# M460 register map
File version: 1.0
Registers are 32-bit, read-write, reset 0x0 unless marked. A register's access mark holds for its fields unless they carry their own. Offsets are from the block's base; [hi:lo] are bit positions.

## CRYPTO — CRYPTO Register Map
Base 0x40032000
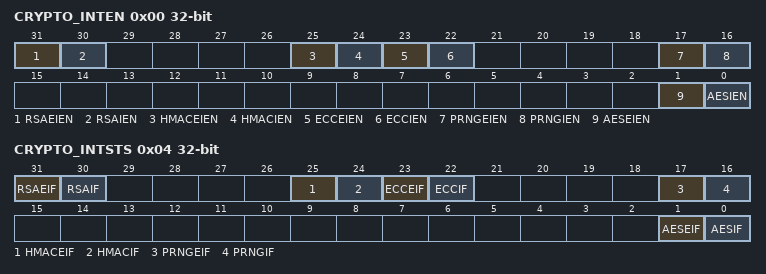
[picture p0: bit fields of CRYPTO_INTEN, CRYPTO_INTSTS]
0x00 CRYPTO_INTEN — Crypto Interrupt Enable Control Register
  [31] RSAEIEN — RSA Error Interrupt Enable Bit
    0=RSA error interrupt flag Disabled; 1=RSA error interrupt flag Enabled
  [30] RSAIEN — RSA Interrupt Enable Bit
    0=RSA interrupt Disabled; 1=RSA interrupt Enabled
  [25] HMACEIEN — SHA/HMAC Error Interrupt Enable Bit
    0=SHA/HMAC error interrupt flag Disabled; 1=HMAC error interrupt flag Enabled
  [24] HMACIEN — SHA/HMAC Interrupt Enable Bit. Note: In DMA mode, an interrupt will be triggered when an amount of data set in HMAC_DMA_CNT is fed into the SHA/HMAC engine. In Non-DMA mode, an interrupt will be triggered when the SHA/HMAC engine finishes the operation.
    0=SHA/HMAC interrupt Disabled; 1=SHA/HMAC interrupt Enabled
  [23] ECCEIEN — ECC Error Interrupt Enable Bit
    0=ECC error interrupt flag Disabled; 1=ECC error interrupt flag Enabled
  [22] ECCIEN — ECC Interrupt Enable Bit. Note: In DMA mode, an interrupt will be triggered when an amount of data set in ECC_DMA_CNT is fed into the ECC engine. In Non-DMA mode, an interrupt will be triggered when the ECC engine finishes the operation.
    0=ECC interrupt Disabled; 1=ECC interrupt Enabled
  [17] PRNGEIEN — PRNG Error Flag Enable Bit
    0=PRNG error interrupt flag Disabled; 1=PRNG error interrupt flag Enabled
  [16] PRNGIEN — PRNG Interrupt Enable Bit
    0=PRNG interrupt Disabled; 1=PRNG interrupt Enabled
  [1] AESEIEN — AES Error Flag Enable Bit
    0=AES error interrupt flag Disabled; 1=AES error interrupt flag Enabled
  [0] AESIEN — AES Interrupt Enable Bit. Note: In DMA mode, an interrupt will be triggered when an amount of data set in AES_DMA_CNT is fed into the AES engine. In Non-DMA mode, an interrupt will be triggered when the AES engine finishes the operation.
    0=AES interrupt Disabled; 1=AES interrupt Enabled
0x04 CRYPTO_INTSTS — Crypto Interrupt Flag
  [31] RSAEIF — RSA Error Interrupt Flag. This register includes operating and setting error. The detail flag is shown in CRYPTO_RSA_STS register. Note: This bit is cleared by writing 1, and it has no effect by writing 0.
    0=No RSA error; 1=RSA error interrupt
  [30] RSAIF — RSA Finish Interrupt Flag. Note: This bit is cleared by writing 1, and it has no effect by writing 0.
    0=No RSA interrupt; 1=RSA operation done interrupt
  [25] HMACEIF — SHA/HMAC Error Flag. This register includes operating and setting error. The detail flag is shown in CRYPTO_HMAC_STS register. Note: This bit is cleared by writing 1, and it has no effect by writing 0.
    0=No SHA/HMAC error; 1=SHA/HMAC error interrupt
  [24] HMACIF — SHA/HMAC Finish Interrupt Flag. Note: This bit is cleared by writing 1, and it has no effect by writing 0.
    0=No SHA/HMAC interrupt; 1=SHA/HMAC operation done interrupt
  [23] ECCEIF — ECC Error Flag. This register includes operating and setting error. The detail flag is shown in CRYPTO_ECC_STS register. Note: This bit is cleared by writing 1, and it has no effect by writing 0.
    0=No ECC error; 1=ECC error interrupt
  [22] ECCIF — ECC Finish Interrupt Flag. Note: This bit is cleared by writing 1, and it has no effect by writing 0.
    0=No ECC interrupt; 1=ECC operation done interrupt
  [17] PRNGEIF — PRNG Error Flag. Note: This bit is cleared by writing 1, and it has no effect by writing 0.
    0=No PRNG error; 1=PRNG key generation error interrupt
  [16] PRNGIF — PRNG Finish Interrupt Flag. Note: This bit is cleared by writing 1, and it has no effect by writing 0.
    0=No PRNG interrupt; 1=PRNG key generation done interrupt
  [1] AESEIF — AES Error Flag. Note: This bit is cleared by writing 1, and it has no effect by writing 0.
    0=No AES error; 1=AES encryption/decryption error interrupt
  [0] AESIF — AES Finish Interrupt Flag. Note: This bit is cleared by writing 1, and it has no effect by writing 0.
    0=No AES interrupt; 1=AES encryption/decryption done interrupt
